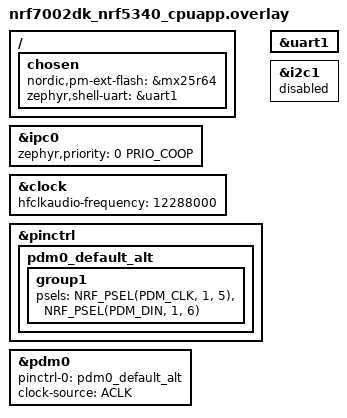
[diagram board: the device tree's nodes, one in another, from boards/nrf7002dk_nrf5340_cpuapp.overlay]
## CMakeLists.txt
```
#
# Copyright (c) 2021 Nordic Semiconductor ASA
#
# SPDX-License-Identifier: LicenseRef-Nordic-5-Clause
#

cmake_minimum_required(VERSION 3.20.0)

get_filename_component(MATTER_MODULE_ROOT $ENV{ZEPHYR_BASE}/../modules/lib/matter REALPATH)

# Set Kconfig root files that will be processed as a first Kconfig for used child images.
set(mcuboot_KCONFIG_ROOT ${MATTER_MODULE_ROOT}/config/nrfconnect/chip-module/Kconfig.mcuboot.root)
set(multiprotocol_rpmsg_KCONFIG_ROOT ${MATTER_MODULE_ROOT}/config/nrfconnect/chip-module/Kconfig.multiprotocol_rpmsg.root)
set(hci_rpmsg_KCONFIG_ROOT ${MATTER_MODULE_ROOT}/config/nrfconnect/chip-module/Kconfig.hci_rpmsg.root)

# For prj.conf the CONF_FILE is empty. In other case extract the exact file name from the path string.
if(CONF_FILE)
    get_filename_component(CONFIG_FILE_NAME ${CONF_FILE} NAME)
endif()

if(NOT CONFIG_FILE_NAME STREQUAL "prj_no_dfu.conf")
    set(PM_STATIC_YML_FILE ${CMAKE_CURRENT_SOURCE_DIR}/configuration/${BOARD}/pm_static_dfu.yml)
endif()

find_package(Zephyr HINTS $ENV{ZEPHYR_BASE})

project(matter-template)

set(COMMON_ROOT ${ZEPHYR_NRF_MODULE_DIR}/samples/matter/common)
set(NLIO_ROOT ${MATTER_MODULE_ROOT}/third_party/nlio/repo)
include(${MATTER_MODULE_ROOT}/config/nrfconnect/app/enable-gnu-std.cmake)
include(${MATTER_MODULE_ROOT}/src/app/chip_data_model.cmake)

# NORDIC SDK APP START
target_include_directories(app PRIVATE
    src
    ${COMMON_ROOT}/src
    ${NLIO_ROOT}/include
    ${MATTER_MODULE_ROOT}/zzz_generated/app-common
)

target_sources(app PRIVATE
    src/app_task.cpp
    src/main.cpp
    src/zap-generated/IMClusterCommandHandler.cpp
    src/zap-generated/callback-stub.cpp
    ${COMMON_ROOT}/src/led_widget.cpp
)

if(CONFIG_CHIP_OTA_REQUESTOR)
    target_sources(app PRIVATE ${COMMON_ROOT}/src/ota_util.cpp)
endif()

chip_configure_data_model(app
    INCLUDE_SERVER
    BYPASS_IDL
    GEN_DIR src/zap-generated
    ZAP_FILE ${CMAKE_CURRENT_SOURCE_DIR}/src/template.zap
)
# NORDIC SDK APP END
```

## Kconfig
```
#
# Copyright (c) 2022 Nordic Semiconductor
#
# SPDX-License-Identifier: LicenseRef-Nordic-5-Clause
#
mainmenu "Matter nRF Connect Template Example Application"

# Sample configuration used for Thread networking
if NET_L2_OPENTHREAD

choice OPENTHREAD_NORDIC_LIBRARY_CONFIGURATION
	default OPENTHREAD_NORDIC_LIBRARY_MTD
endchoice

choice OPENTHREAD_DEVICE_TYPE
	default OPENTHREAD_MTD
endchoice

endif # NET_L2_OPENTHREAD

source "${ZEPHYR_BASE}/../modules/lib/matter/config/nrfconnect/chip-module/Kconfig.features"
source "${ZEPHYR_BASE}/../modules/lib/matter/config/nrfconnect/chip-module/Kconfig.defaults"
source "Kconfig.zephyr"
```

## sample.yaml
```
sample:
  description: Matter Template sample
  name: Matter Template
tests:
  # Excluded in quarantine.yaml to limit resources usage in integration builds
  sample.matter.template.release:
    build_only: true
    extra_args: CONF_FILE=prj_release.conf
    integration_platforms:
      - nrf52840dk_nrf52840
      - nrf5340dk_nrf5340_cpuapp
      - nrf7002dk_nrf5340_cpuapp
    platform_allow: nrf52840dk_nrf52840 nrf5340dk_nrf5340_cpuapp nrf7002dk_nrf5340_cpuapp
  sample.matter.template.no_dfu:
    build_only: true
    extra_args: CONF_FILE=prj_no_dfu.conf
    integration_platforms:
      - nrf21540dk_nrf52840
    platform_allow: >
      nrf52840dk_nrf52840 nrf21540dk_nrf52840 nrf5340dk_nrf5340_cpuapp nrf7002dk_nrf5340_cpuapp
  sample.matter.template.debug:
    build_only: true
    integration_platforms:
      - nrf5340dk_nrf5340_cpuapp
      - nrf7002dk_nrf5340_cpuapp
    platform_allow: nrf52840dk_nrf52840 nrf5340dk_nrf5340_cpuapp nrf7002dk_nrf5340_cpuapp
```

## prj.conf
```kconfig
#
# Copyright (c) 2021 Nordic Semiconductor ASA
#
# SPDX-License-Identifier: LicenseRef-Nordic-5-Clause
#

# This sample uses Kconfig.defaults to set options common for all
# samples. This file should contain only options specific for this sample
# or overrides of default values.

# Enable CHIP
CONFIG_CHIP=y
CONFIG_CHIP_ENABLE_PAIRING_AUTOSTART=y
CONFIG_CHIP_PROJECT_CONFIG="src/chip_project_config.h"
# 32768 == 0x8000 (example Product ID added temporaly,
# but it must be changed with proper PID from the list:
# https://github.com/project-chip/connectedhomeip/blob/482e6fd03196a6de45465a90003947ef4b86e0b1/docs/examples/discussion/PID_allocation_for_example_apps.md)
CONFIG_CHIP_DEVICE_PRODUCT_ID=32768
CONFIG_STD_CPP14=y

# Add support for LEDs and buttons on Nordic development kits
CONFIG_DK_LIBRARY=y

# Bluetooth Low Energy configuration
CONFIG_BT_DEVICE_NAME="MatterTemplate"

# Other settings
CONFIG_THREAD_NAME=y
CONFIG_MPU_STACK_GUARD=y
CONFIG_RESET_ON_FATAL_ERROR=n
CONFIG_CHIP_LIB_SHELL=y

# Disable NFC commissioning
CONFIG_CHIP_NFC_COMMISSIONING=n

# Reduce application size
CONFIG_USE_SEGGER_RTT=n

CONFIG_AUDIO=y
CONFIG_AUDIO_DMIC=y
CONFIG_SYSTEM_WORKQUEUE_STACK_SIZE=4096
CONFIG_HEAP_MEM_POOL_SIZE=8192
CONFIG_MAIN_STACK_SIZE=2048

CONFIG_SERIAL=y
CONFIG_UART_ASYNC_API=y
```

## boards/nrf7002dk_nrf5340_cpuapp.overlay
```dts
#include <zephyr/dt-bindings/ipc_service/static_vrings.h>
/delete-node/ &gpio_fwd; /* for UART1 usage */
/ {
	chosen {
		nordic,pm-ext-flash = &mx25r64;
		zephyr,shell-uart = &uart1;
	};
};
/* Set IPC thread priority to the highest value to not collide with other threads. */
&ipc0 {
    zephyr,priority = <0 PRIO_COOP>;
};

&clock {
    hfclkaudio-frequency = <12288000>;
};
&pinctrl {
    pdm0_default_alt: pdm0_default_alt {
        group1 {
            psels = <NRF_PSEL(PDM_CLK, 1, 5)>,
                <NRF_PSEL(PDM_DIN, 1, 6)>;
        };
    };
};
dmic_dev: &pdm0 {
    status = "okay";
    pinctrl-0 = <&pdm0_default_alt>;
    pinctrl-names = "default";
    clock-source = "ACLK";
};

&uart1 {
    status = "okay";
};

&i2c1 {
	status = "disabled";
};
```

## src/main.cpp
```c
/*
 * Copyright (c) 2021 Nordic Semiconductor ASA
 *
 * SPDX-License-Identifier: LicenseRef-Nordic-5-Clause
 */

#include "app_task.h"
#include <zephyr/device.h>
#include <zephyr/audio/dmic.h>
#include <zephyr/drivers/uart.h>
#include <zephyr/logging/log.h>


LOG_MODULE_REGISTER(app, CONFIG_CHIP_APP_LOG_LEVEL);

/* DMIC configure */
#define MAX_SAMPLE_RATE  16000
#define SAMPLE_BIT_WIDTH 16
#define BYTES_PER_SAMPLE sizeof(int16_t)
#define READ_TIMEOUT     1000

/* Size of a block for 100 ms of audio data. */
#define BLOCK_SIZE(_sample_rate, _number_of_channels) (BYTES_PER_SAMPLE * (_sample_rate / 10) * _number_of_channels)
#define MAX_BLOCK_SIZE   BLOCK_SIZE(MAX_SAMPLE_RATE, 2)
#define BLOCK_COUNT      4

K_MEM_SLAB_DEFINE_STATIC(mem_slab, MAX_BLOCK_SIZE, BLOCK_COUNT, 4);

float audio[16000];

/* DMIC audio */
static int do_pdm_transfer(const struct device *dmic_dev, struct dmic_cfg *cfg, size_t block_count) {
	int ret;

	LOG_INF("Starting sampling:");

	/* Start the microphone. */
	ret = dmic_trigger(dmic_dev, DMIC_TRIGGER_START);
	if (ret) {
		LOG_INF("dmic_trigger failed: %d\n", ret);
		return ret;
	}
	
	for (int i = 0; i < 11; ++i) {
		void *buffer;
		uint32_t size;

		ret = dmic_read(dmic_dev, 0, &buffer, &size, READ_TIMEOUT);
		if (ret) {
			LOG_INF("dmic_read failed: %d\n", ret);
			break;
		}

		/* Discard first readout due to microphone needing to 
		 * stabilize before valid data can be read. */
		if (i != 0) {
			int16_t tempInt;
			float tempFloat;
			for(int j = 0; j < 1600; j++) {
				memcpy(&tempInt, buffer + 2*j, 2);
				tempFloat = (float)tempInt;
				audio[(i-1)*1600+j] = tempFloat;
			}
		}
		k_mem_slab_free(&mem_slab, &buffer);
	}

	/* Stop the microphone. */
	ret = dmic_trigger(dmic_dev, DMIC_TRIGGER_STOP);
	if (ret) {
		return ret;
	}
	return 0;
}

/* UART callback */
static void uart_cb(const struct device *dev, struct uart_event *evt, void *user_data)
{
	switch (evt->type) {
	case UART_TX_DONE: /* Transfer data done */
		LOG_INF("Transmit data successful\n");
	case UART_TX_ABORTED:
		LOG_INF("Transmit data failed\n");
	default:
		break;
	}
}

int main()
{
	int ret;

	/* Init Matter */
	CHIP_ERROR err = AppTask::Instance().StartApp();
	LOG_ERR("Exited with code %" CHIP_ERROR_FORMAT, err.Format());
	return err == CHIP_NO_ERROR ? EXIT_SUCCESS : EXIT_FAILURE;

	/* Init UART1 */
	const struct device *uart= DEVICE_DT_GET(DT_NODELABEL(uart1));
	if (!device_is_ready(uart)){
		LOG_ERR("UART device not ready\n");
		return 1;
	}

	ret = uart_callback_set(uart, uart_cb, NULL);
	if (ret) {
		printk("uart_callback_set error: %d\n", ret);
		return 1;
	}

	/* Init DMIC */
	const struct device *dmic_dev = DEVICE_DT_GET(DT_NODELABEL(dmic_dev));
	if (!device_is_ready(dmic_dev)) {
		LOG_ERR("DMIC device not ready\n");
        return EXIT_FAILURE;
	}

	/* DMIC configuration */
	struct pcm_stream_cfg stream = {
		.pcm_width = SAMPLE_BIT_WIDTH,
		.mem_slab  = &mem_slab,
	};
	
	struct dmic_cfg cfg = {
		.io = {
			.min_pdm_clk_freq = 1100000,
			.max_pdm_clk_freq = 3500000,
			.min_pdm_clk_dc   = 40,
			.max_pdm_clk_dc   = 60,
		},
		.streams = &stream,
		.channel = {
			.req_num_streams = 1,
		},
	};

	cfg.channel.req_num_chan = 1;
	cfg.channel.req_chan_map_lo = dmic_build_channel_map(0, 0, PDM_CHAN_LEFT);
	cfg.streams[0].pcm_rate = MAX_SAMPLE_RATE;
	cfg.streams[0].block_size = BLOCK_SIZE(cfg.streams[0].pcm_rate, cfg.channel.req_num_chan);

	ret = dmic_configure(dmic_dev, &cfg);
	if (ret) {
		LOG_ERR("dmic_configure failed: %d\n", ret);
        return EXIT_FAILURE;
	}

	/* main loop */
	while(1) {
		/* Record audio */
		ret = do_pdm_transfer(dmic_dev, &cfg, 2 * BLOCK_COUNT);
		if (ret) {
			LOG_ERR("do_pdm_transfer failed: %d\n", ret);
			return EXIT_FAILURE;
		}
		/* Transfer data via UART */
		for (int i = 0; i < 16000; i++) {
			char audio_buf[sizeof(float)];
			uint8_t tx_buf[sizeof(float)];
			sprintf(audio_buf, "%0.7f", audio[i]);
			memcpy(tx_buf, audio_buf, sizeof(float));
			ret = uart_tx(uart, tx_buf, sizeof(tx_buf), SYS_FOREVER_US);
			if (ret) {
				return EXIT_FAILURE;
			}
		}
		k_sleep(K_SECONDS(2));
	}
}
```

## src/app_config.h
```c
/*
 * Copyright (c) 2022 Nordic Semiconductor ASA
 *
 * SPDX-License-Identifier: LicenseRef-Nordic-5-Clause
 */

#pragma once

/* ---- Template App Config ---- */

#include "board_util.h"

#define FUNCTION_BUTTON DK_BTN1
#define FUNCTION_BUTTON_MASK DK_BTN1_MSK

#define SYSTEM_STATE_LED DK_LED1
#define FACTORY_RESET_SIGNAL_LED DK_LED2

#if NUMBER_OF_LEDS == 4
#define FACTORY_RESET_SIGNAL_LED1 DK_LED3
#define FACTORY_RESET_SIGNAL_LED2 DK_LED4
#endif
```

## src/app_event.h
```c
/*
 * Copyright (c) 2021 Nordic Semiconductor ASA
 *
 * SPDX-License-Identifier: LicenseRef-Nordic-5-Clause
 */

#pragma once

#include <cstdint>

#include "event_types.h"

class LEDWidget;

enum class AppEventType : uint8_t { None = 0, Button, ButtonPushed, ButtonReleased, Timer, UpdateLedState };

enum class FunctionEvent : uint8_t { NoneSelected = 0, FactoryReset };

struct AppEvent {
	union {
		struct {
			uint8_t PinNo;
			uint8_t Action;
		} ButtonEvent;
		struct {
			void *Context;
		} TimerEvent;
		struct {
			LEDWidget *LedWidget;
		} UpdateLedStateEvent;
	};

	AppEventType Type{ AppEventType::None };
	EventHandler Handler;
};
```

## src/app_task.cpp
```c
/*
 * Copyright (c) 2021 Nordic Semiconductor ASA
 *
 * SPDX-License-Identifier: LicenseRef-Nordic-5-Clause
 */

#include "app_task.h"
#include "app_config.h"
#include "led_util.h"

#include <platform/CHIPDeviceLayer.h>

#include "board_util.h"
#include <app/server/OnboardingCodesUtil.h>
#include <app/server/Server.h>
#include <credentials/DeviceAttestationCredsProvider.h>
#include <credentials/examples/DeviceAttestationCredsExample.h>
#include <lib/support/CHIPMem.h>
#include <lib/support/CodeUtils.h>
#include <system/SystemError.h>

#ifdef CONFIG_CHIP_WIFI
#include <app/clusters/network-commissioning/network-commissioning.h>
#include <platform/nrfconnect/wifi/NrfWiFiDriver.h>
#endif

#ifdef CONFIG_CHIP_OTA_REQUESTOR
#include "ota_util.h"
#endif

#include <dk_buttons_and_leds.h>
#include <zephyr/kernel.h>
#include <zephyr/logging/log.h>

LOG_MODULE_DECLARE(app, CONFIG_CHIP_APP_LOG_LEVEL);

using namespace ::chip;
using namespace ::chip::app;
using namespace ::chip::Credentials;
using namespace ::chip::DeviceLayer;

namespace
{
constexpr size_t kAppEventQueueSize = 10;
constexpr uint32_t kFactoryResetTriggerTimeout = 6000;

K_MSGQ_DEFINE(sAppEventQueue, sizeof(AppEvent), kAppEventQueueSize, alignof(AppEvent));
k_timer sFunctionTimer;

LEDWidget sStatusLED;
#if NUMBER_OF_LEDS == 2
FactoryResetLEDsWrapper<1> sFactoryResetLEDs{ { FACTORY_RESET_SIGNAL_LED } };
#else
FactoryResetLEDsWrapper<3> sFactoryResetLEDs{ { FACTORY_RESET_SIGNAL_LED, FACTORY_RESET_SIGNAL_LED1,
						FACTORY_RESET_SIGNAL_LED2 } };
#endif

bool sIsNetworkProvisioned = false;
bool sIsNetworkEnabled = false;
bool sHaveBLEConnections = false;
} /* namespace */

namespace LedConsts
{
namespace StatusLed
{
	namespace Unprovisioned
	{
		constexpr uint32_t kOn_ms{ 100 };
		constexpr uint32_t kOff_ms{ kOn_ms };
	} /* namespace Unprovisioned */
	namespace Provisioned
	{
		constexpr uint32_t kOn_ms{ 50 };
		constexpr uint32_t kOff_ms{ 950 };
	} /* namespace Provisioned */

} /* namespace StatusLed */
} /* namespace LedConsts */

#ifdef CONFIG_CHIP_WIFI
app::Clusters::NetworkCommissioning::Instance
	sWiFiCommissioningInstance(0, &(NetworkCommissioning::NrfWiFiDriver::Instance()));
#endif

CHIP_ERROR AppTask::Init()
{
	/* Initialize CHIP stack */
	LOG_INF("Init CHIP stack");

	CHIP_ERROR err = chip::Platform::MemoryInit();
	if (err != CHIP_NO_ERROR) {
		LOG_ERR("Platform::MemoryInit() failed");
		return err;
	}

	err = PlatformMgr().InitChipStack();
	if (err != CHIP_NO_ERROR) {
		LOG_ERR("PlatformMgr().InitChipStack() failed");
		return err;
	}

#if defined(CONFIG_NET_L2_OPENTHREAD)
	err = ThreadStackMgr().InitThreadStack();
	if (err != CHIP_NO_ERROR) {
		LOG_ERR("ThreadStackMgr().InitThreadStack() failed: %s", ErrorStr(err));
		return err;
	}

#ifdef CONFIG_OPENTHREAD_MTD_SED
	err = ConnectivityMgr().SetThreadDeviceType(ConnectivityManager::kThreadDeviceType_SleepyEndDevice);
#elif CONFIG_OPENTHREAD_MTD
	err = ConnectivityMgr().SetThreadDeviceType(ConnectivityManager::kThreadDeviceType_MinimalEndDevice);
#else
	err = ConnectivityMgr().SetThreadDeviceType(ConnectivityManager::kThreadDeviceType_Router);
#endif /* CONFIG_OPENTHREAD_MTD_SED */
	if (err != CHIP_NO_ERROR) {
		LOG_ERR("ConnectivityMgr().SetThreadDeviceType() failed: %s", ErrorStr(err));
		return err;
	}

#elif defined(CONFIG_CHIP_WIFI)
	sWiFiCommissioningInstance.Init();
#else
	return CHIP_ERROR_INTERNAL;
#endif /* CONFIG_NET_L2_OPENTHREAD */

	/* Initialize LEDs */
	LEDWidget::InitGpio();
	LEDWidget::SetStateUpdateCallback(LEDStateUpdateHandler);

	sStatusLED.Init(SYSTEM_STATE_LED);

	UpdateStatusLED();

	/* Initialize buttons */
	int ret = dk_buttons_init(ButtonEventHandler);
	if (ret) {
		LOG_ERR("dk_buttons_init() failed");
		return chip::System::MapErrorZephyr(ret);
	}

	/* Initialize function timer */
	k_timer_init(&sFunctionTimer, &AppTask::FunctionTimerTimeoutCallback, nullptr);
	k_timer_user_data_set(&sFunctionTimer, this);

	/* Initialize CHIP server */
#if CONFIG_CHIP_FACTORY_DATA
	ReturnErrorOnFailure(mFactoryDataProvider.Init());
	SetDeviceInstanceInfoProvider(&mFactoryDataProvider);
	SetDeviceAttestationCredentialsProvider(&mFactoryDataProvider);
	SetCommissionableDataProvider(&mFactoryDataProvider);
#else
	SetDeviceInstanceInfoProvider(&DeviceInstanceInfoProviderMgrImpl());
	SetDeviceAttestationCredentialsProvider(Examples::GetExampleDACProvider());
#endif

	static chip::CommonCaseDeviceServerInitParams initParams;
	(void)initParams.InitializeStaticResourcesBeforeServerInit();

	ReturnErrorOnFailure(chip::Server::GetInstance().Init(initParams));
	ConfigurationMgr().LogDeviceConfig();
	PrintOnboardingCodes(chip::RendezvousInformationFlags(chip::RendezvousInformationFlag::kBLE));

	/*
	 * Add CHIP event handler and start CHIP thread.
	 * Note that all the initialization code should happen prior to this point to avoid data races
	 * between the main and the CHIP threads.
	 */
	PlatformMgr().AddEventHandler(ChipEventHandler, 0);

	err = PlatformMgr().StartEventLoopTask();
	if (err != CHIP_NO_ERROR) {
		LOG_ERR("PlatformMgr().StartEventLoopTask() failed");
		return err;
	}

	return CHIP_NO_ERROR;
}

CHIP_ERROR AppTask::StartApp()
{
	ReturnErrorOnFailure(Init());

	AppEvent event = {};

	while (true) {
		k_msgq_get(&sAppEventQueue, &event, K_FOREVER);
		DispatchEvent(event);
	}

	return CHIP_NO_ERROR;
}

void AppTask::ButtonEventHandler(uint32_t buttonState, uint32_t hasChanged)
{
	AppEvent button_event;
	button_event.Type = AppEventType::Button;

	if (FUNCTION_BUTTON_MASK & hasChanged) {
		button_event.ButtonEvent.PinNo = FUNCTION_BUTTON;
		button_event.ButtonEvent.Action =
			static_cast<uint8_t>((FUNCTION_BUTTON_MASK & buttonState) ? AppEventType::ButtonPushed :
										    AppEventType::ButtonReleased);
		button_event.Handler = FunctionHandler;
		PostEvent(button_event);
	}
}

void AppTask::FunctionTimerTimeoutCallback(k_timer *timer)
{
	if (!timer) {
		return;
	}

	AppEvent event;
	event.Type = AppEventType::Timer;
	event.TimerEvent.Context = k_timer_user_data_get(timer);
	event.Handler = FunctionTimerEventHandler;
	PostEvent(event);
}

void AppTask::FunctionTimerEventHandler(const AppEvent &)
{
	if (Instance().mFunction == FunctionEvent::FactoryReset) {
		Instance().mFunction = FunctionEvent::NoneSelected;
		LOG_INF("Factory Reset triggered");

		sStatusLED.Set(true);
		sFactoryResetLEDs.Set(true);

		chip::Server::GetInstance().ScheduleFactoryReset();
	}
}

void AppTask::FunctionHandler(const AppEvent &event)
{
	if (event.ButtonEvent.PinNo != FUNCTION_BUTTON)
		return;

	if (event.ButtonEvent.Action == static_cast<uint8_t>(AppEventType::ButtonPushed)) {
		Instance().StartTimer(kFactoryResetTriggerTimeout);
		Instance().mFunction = FunctionEvent::FactoryReset;
	} else if (event.ButtonEvent.Action == static_cast<uint8_t>(AppEventType::ButtonReleased)) {
		if (Instance().mFunction == FunctionEvent::FactoryReset) {
			sFactoryResetLEDs.Set(false);
			UpdateStatusLED();
			Instance().CancelTimer();
			Instance().mFunction = FunctionEvent::NoneSelected;
			LOG_INF("Factory Reset has been Canceled");
		}
	}
}

void AppTask::LEDStateUpdateHandler(LEDWidget &ledWidget)
{
	AppEvent event;
	event.Type = AppEventType::UpdateLedState;
	event.Handler = UpdateLedStateEventHandler;
	event.UpdateLedStateEvent.LedWidget = &ledWidget;
	PostEvent(event);
}

void AppTask::UpdateLedStateEventHandler(const AppEvent &event)
{
	if (event.Type == AppEventType::UpdateLedState) {
		event.UpdateLedStateEvent.LedWidget->UpdateState();
	}
}

void AppTask::UpdateStatusLED()
{
	/* Update the status LED.
	 *
	 * If IPv6 networking and service provisioned, keep the LED On constantly.
	 *
	 * If the system has BLE connection(s) uptill the stage above, THEN blink the LED at an even
	 * rate of 100ms.
	 *
	 * Otherwise, blink the LED for a very short time. */
	if (sIsNetworkProvisioned && sIsNetworkEnabled) {
		sStatusLED.Set(true);
	} else if (sHaveBLEConnections) {
		sStatusLED.Blink(LedConsts::StatusLed::Unprovisioned::kOn_ms,
				 LedConsts::StatusLed::Unprovisioned::kOff_ms);
	} else {
		sStatusLED.Blink(LedConsts::StatusLed::Provisioned::kOn_ms, LedConsts::StatusLed::Provisioned::kOff_ms);
	}
}

void AppTask::ChipEventHandler(const ChipDeviceEvent *event, intptr_t /* arg */)
{
	switch (event->Type) {
	case DeviceEventType::kCHIPoBLEAdvertisingChange:
		sHaveBLEConnections = ConnectivityMgr().NumBLEConnections() != 0;
		UpdateStatusLED();
		break;
#if defined(CONFIG_NET_L2_OPENTHREAD)
	case DeviceEventType::kDnssdInitialized:
#if CONFIG_CHIP_OTA_REQUESTOR
		InitBasicOTARequestor();
#endif /* CONFIG_CHIP_OTA_REQUESTOR */
		break;
	case DeviceEventType::kThreadStateChange:
		sIsNetworkProvisioned = ConnectivityMgr().IsThreadProvisioned();
		sIsNetworkEnabled = ConnectivityMgr().IsThreadEnabled();
#elif defined(CONFIG_CHIP_WIFI)
	case DeviceEventType::kWiFiConnectivityChange:
		sIsNetworkProvisioned = ConnectivityMgr().IsWiFiStationProvisioned();
		sIsNetworkEnabled = ConnectivityMgr().IsWiFiStationEnabled();
#if CONFIG_CHIP_OTA_REQUESTOR
		if (event->WiFiConnectivityChange.Result == kConnectivity_Established) {
			InitBasicOTARequestor();
		}
#endif /* CONFIG_CHIP_OTA_REQUESTOR */
#endif
		UpdateStatusLED();
		break;
	default:
		break;
	}
}

void AppTask::CancelTimer()
{
	k_timer_stop(&sFunctionTimer);
}

void AppTask::StartTimer(uint32_t timeoutInMs)
{
	k_timer_start(&sFunctionTimer, K_MSEC(timeoutInMs), K_NO_WAIT);
}

void AppTask::PostEvent(const AppEvent &event)
{
	if (k_msgq_put(&sAppEventQueue, &event, K_NO_WAIT) != 0) {
		LOG_INF("Failed to post event to app task event queue");
	}
}

void AppTask::DispatchEvent(const AppEvent &event)
{
	if (event.Handler) {
		event.Handler(event);
	} else {
		LOG_INF("Event received with no handler. Dropping event.");
	}
}
```

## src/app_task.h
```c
/*
 * Copyright (c) 2021 Nordic Semiconductor ASA
 *
 * SPDX-License-Identifier: LicenseRef-Nordic-5-Clause
 */

#pragma once

#include "app_event.h"
#include "led_widget.h"

#include <platform/CHIPDeviceLayer.h>

#if CONFIG_CHIP_FACTORY_DATA
#include <platform/nrfconnect/FactoryDataProvider.h>
#else
#include <platform/nrfconnect/DeviceInstanceInfoProviderImpl.h>
#endif

struct k_timer;

class AppTask {
public:
	static AppTask &Instance()
	{
		static AppTask sAppTask;
		return sAppTask;
	};

	CHIP_ERROR StartApp();

	static void PostEvent(const AppEvent &event);

private:
	CHIP_ERROR Init();

	void CancelTimer();
	void StartTimer(uint32_t timeoutInMs);

	static void DispatchEvent(const AppEvent &event);
	static void UpdateLedStateEventHandler(const AppEvent &event);
	static void FunctionHandler(const AppEvent &event);
	static void FunctionTimerEventHandler(const AppEvent &event);

	static void ChipEventHandler(const chip::DeviceLayer::ChipDeviceEvent *event, intptr_t arg);
	static void ButtonEventHandler(uint32_t buttonState, uint32_t hasChanged);
	static void LEDStateUpdateHandler(LEDWidget &ledWidget);
	static void FunctionTimerTimeoutCallback(k_timer *timer);
	static void UpdateStatusLED();

	FunctionEvent mFunction = FunctionEvent::NoneSelected;
	bool mFunctionTimerActive = false;

#if CONFIG_CHIP_FACTORY_DATA
	chip::DeviceLayer::FactoryDataProvider<chip::DeviceLayer::InternalFlashFactoryData> mFactoryDataProvider;
#endif
};
```
